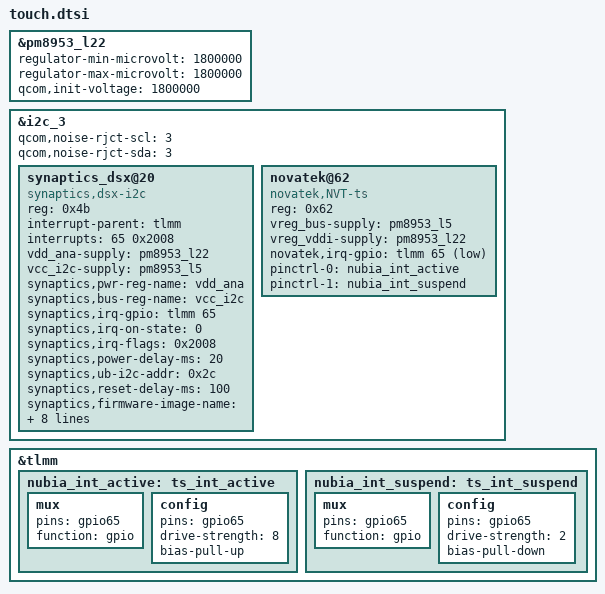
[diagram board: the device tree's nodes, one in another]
/*
 * Copyright (c) 2015-2016, The Linux Foundation. All rights reserved.
 *
 * This program is free software; you can redistribute it and/or modify
 * it under the terms of the GNU General Public License version 2 and
 * only version 2 as published by the Free Software Foundation.
 *
 * This program is distributed in the hope that it will be useful,
 * but WITHOUT ANY WARRANTY; without even the implied warranty of
 * MERCHANTABILITY or FITNESS FOR A PARTICULAR PURPOSE.  See the
 * GNU General Public License for more details.
 */


/*
 * ADD synaptics touch
 */

&pm8953_l22 {
	regulator-min-microvolt = <1800000>;
	regulator-max-microvolt = <1800000>;
	qcom,init-voltage = <1800000>;
};

&i2c_3 {
	status = "okay";

	qcom,noise-rjct-scl = <3>;
	qcom,noise-rjct-sda = <3>;

	synaptics_dsx@20 {
		status = "okay";
		compatible = "synaptics,dsx-i2c";
		reg = <0x4b>;
		interrupt-parent = <&tlmm>;
		interrupts = <65 0x2008>;
		vdd_ana-supply = <&pm8953_l22>;
		vcc_i2c-supply = <&pm8953_l5>;
		synaptics,pwr-reg-name = "vdd_ana";
		synaptics,bus-reg-name = "vcc_i2c";
		synaptics,irq-gpio = <&tlmm 65 0x2008>;
		synaptics,irq-on-state = <0>;
		synaptics,irq-flags = <0x2008>;  //IRQF_ONESHOT | IRQF_TRIGGER_LOW
		synaptics,power-delay-ms = <20>;
		synaptics,ub-i2c-addr = <0x2c>;
		synaptics,reset-delay-ms = <100>;
		synaptics,firmware-image-name = "nubia_tp_jdi_fw.img";
		pinctrl-names = "synaptics_pin_active", "synaptics_pin_suspend";
		pinctrl-0 = <&nubia_int_active>;
		pinctrl-1 = <&nubia_int_suspend>;
		synaptics.test = <0xaa55 0x1122 0x3344 0x8899>;
		synaptics,full_raw_limit_lower = <
			1767 1760 1731 1716 1749 1706 1709 1710 1676 1674 1706 1667 1661 1682 1637 1634 1682 1639 1656 1675 1655 1655 1679 1658 1675 1715 1674 1695 1730 1673 1707 1763
			1598 1619 1595 1593 1632 1599 1607 1615 1593 1596 1651 1596 1608 1627 1586 1591 1639 1601 1615 1639 1615 1620 1641 1622 1642 1685 1642 1667 1699 1642 1673 1731
			1595 1613 1592 1591 1632 1597 1606 1614 1595 1597 1639 1600 1604 1630 1590 1595 1644 1606 1621 1646 1622 1627 1650 1630 1650 1694 1648 1675 1705 1647 1677 1735
			1595 1611 1590 1590 1631 1595 1605 1617 1595 1602 1644 1602 1607 1641 1593 1599 1653 1609 1626 1655 1627 1634 1665 1635 1659 1704 1652 1681 1719 1647 1693 1746
			1602 1623 1588 1595 1634 1594 1610 1616 1596 1609 1645 1604 1615 1641 1595 1605 1657 1612 1635 1655 1632 1644 1668 1639 1666 1706 1654 1685 1719 1649 1694 1745
			1603 1617 1587 1593 1628 1592 1608 1617 1595 1608 1648 1604 1616 1643 1596 1607 1658 1613 1637 1658 1634 1647 1671 1640 1667 1706 1652 1683 1716 1647 1692 1741
			1603 1617 1587 1593 1628 1591 1607 1616 1595 1609 1648 1605 1617 1644 1597 1609 1659 1615 1639 1659 1635 1648 1671 1642 1668 1707 1652 1683 1716 1647 1694 1741
			1605 1617 1588 1593 1627 1590 1607 1615 1594 1608 1648 1605 1617 1644 1597 1609 1660 1615 1639 1662 1635 1649 1674 1641 1666 1709 1648 1683 1729 1645 1681 1713
			1600 1590 1589 1579 1626 1590 1601 1617 1594 1603 1648 1606 1610 1645 1597 1603 1660 1616 1635 1664 1636 1644 1671 1641 1659 1702 1648 1669 1706 1645 1674 1735
			1569 1549 1572 1539 1540 1590 1548 1558 1570 1545 1560 1593 1552 1560 1607 1554 1581 1602 1583 1589 1627 1590 1608 1647 1620 1617 1654 1612 1624 1631 1610 1651
			1554 1563 1595 1539 1558 1598 1548 1563 1574 1545 1566 1591 1551 1566 1606 1553 1587 1603 1582 1596 1622 1589 1615 1646 1620 1624 1657 1612 1639 1659 1610 1664
			1552 1567 1583 1539 1556 1593 1548 1562 1570 1545 1566 1586 1551 1565 1605 1551 1585 1601 1580 1594 1621 1588 1614 1646 1620 1624 1657 1612 1638 1658 1608 1658
			1551 1566 1583 1540 1557 1594 1549 1562 1570 1545 1565 1586 1550 1563 1603 1550 1583 1600 1579 1592 1619 1587 1612 1644 1618 1623 1656 1611 1636 1657 1606 1654
			1549 1566 1583 1541 1556 1594 1551 1563 1570 1544 1563 1584 1548 1561 1601 1548 1580 1597 1576 1588 1616 1583 1609 1637 1616 1622 1654 1610 1635 1657 1603 1652
			1549 1561 1586 1541 1554 1598 1550 1560 1571 1542 1556 1584 1545 1553 1599 1545 1572 1592 1570 1579 1614 1578 1597 1635 1611 1612 1647 1608 1625 1645 1599 1641
			1549 1553 1576 1541 1551 1591 1552 1556 1563 1540 1552 1576 1542 1549 1590 1541 1566 1580 1566 1571 1602 1572 1589 1625 1606 1606 1640 1604 1622 1641 1595 1635
			1553 1556 1577 1543 1551 1592 1553 1555 1560 1536 1548 1572 1538 1545 1585 1538 1561 1575 1561 1573 1612 1565 1584 1618 1600 1600 1638 1601 1617 1635 1592 1631
			1599 1594 1615 1580 1589 1626 1591 1592 1597 1575 1581 1612 1579 1586 1626 1579 1605 1624 1615 1624 1658 1637 1655 1699 1689 1696 1737 1708 1734 1759 1726 1782
		>;
		synaptics,full_raw_limit_upper = <
			3281 3268 3214 3187 3248 3169 3174 3176 3113 3109 3169 3096 3084 3124 3040 3034 3124 3044 3076 3111 3073 3073 3118 3079 3111 3184 3108 3147 3213 3108 3170 3274
			2969 3007 2963 2958 3032 2970 2984 2999 2958 2963 3067 2964 2985 3022 2946 2954 3044 2974 2999 3044 3000 3008 3048 3012 3050 3130 3049 3097 3155 3050 3106 3215
			2961 2996 2957 2956 3031 2965 2983 2998 2962 2967 3045 2972 2979 3027 2953 2962 3053 2982 3010 3056 3013 3022 3065 3027 3065 3145 3061 3110 3167 3058 3114 3223
			2963 2993 2952 2952 3028 2962 2982 3002 2963 2974 3054 2975 2985 3048 2958 2969 3069 2988 3019 3073 3021 3035 3092 3036 3081 3165 3068 3121 3193 3059 3144 3243
			2976 3013 2948 2962 3035 2960 2990 3001 2964 2989 3055 2978 2998 3048 2963 2981 3077 2995 3037 3074 3031 3053 3097 3044 3094 3168 3072 3129 3192 3063 3145 3240
			2977 3002 2946 2959 3024 2956 2987 3003 2962 2987 3060 2980 3001 3052 2965 2985 3079 2996 3040 3079 3035 3058 3102 3046 3096 3169 3068 3125 3187 3058 3143 3233
			2978 3002 2947 2959 3023 2955 2985 3002 2962 2988 3061 2981 3003 3053 2965 2988 3081 2999 3043 3081 3037 3061 3104 3049 3098 3170 3067 3126 3188 3058 3146 3233
			2981 3003 2948 2959 3022 2953 2985 3000 2959 2987 3061 2981 3003 3053 2965 2988 3083 3000 3044 3087 3036 3062 3109 3047 3095 3173 3061 3126 3212 3055 3122 3182
			2971 2952 2951 2932 3021 2952 2973 3003 2961 2976 3060 2982 2990 3054 2966 2977 3082 3001 3036 3091 3038 3053 3104 3048 3081 3160 3061 3099 3169 3054 3109 3223
			2913 2877 2920 2859 2860 2953 2875 2894 2916 2869 2897 2958 2883 2898 2984 2885 2936 2975 2940 2951 3022 2953 2985 3059 3008 3002 3071 2993 3015 3028 2990 3066
			2886 2903 2962 2857 2893 2968 2874 2902 2922 2869 2909 2955 2881 2909 2982 2883 2948 2977 2938 2963 3013 2952 3000 3058 3008 3017 3077 2994 3044 3082 2991 3091
			2883 2910 2939 2859 2890 2958 2875 2902 2915 2869 2908 2946 2880 2907 2980 2881 2944 2974 2934 2961 3011 2949 2998 3057 3008 3017 3078 2994 3041 3079 2986 3079
			2881 2909 2939 2859 2891 2960 2877 2901 2915 2869 2906 2945 2878 2904 2977 2878 2940 2971 2932 2956 3007 2947 2993 3052 3005 3014 3075 2992 3039 3076 2983 3072
			2876 2908 2939 2862 2890 2961 2880 2903 2916 2868 2904 2942 2876 2898 2974 2875 2935 2966 2927 2950 3000 2940 2989 3041 3001 3012 3071 2990 3036 3078 2976 3068
			2877 2899 2945 2861 2886 2967 2879 2898 2917 2864 2890 2943 2870 2884 2969 2869 2919 2956 2917 2932 2998 2930 2967 3036 2993 2994 3058 2986 3018 3056 2969 3047
			2876 2883 2927 2863 2880 2955 2882 2889 2902 2859 2881 2926 2865 2876 2952 2862 2908 2934 2908 2918 2976 2920 2951 3017 2983 2983 3046 2980 3012 3048 2962 3036
			2884 2889 2929 2866 2880 2957 2884 2887 2897 2853 2874 2919 2857 2869 2944 2856 2900 2925 2899 2922 2993 2907 2941 3006 2971 2971 3042 2973 3003 3037 2957 3028
			2969 2961 3000 2935 2951 3019 2956 2957 2965 2924 2937 2993 2932 2945 3020 2933 2981 3016 3000 3016 3079 3040 3074 3155 3137 3149 3226 3173 3220 3267 3205 3310
			>;
	};

	/* Novatek device tree node */
	novatek@62 {
		compatible = "novatek,NVT-ts";
		reg = <0x62>;
		status = "ok";

		vreg_bus-supply = <&pm8953_l5>;	//pullup
		/*add this to keep vddio enable after suspend*/
		vreg_vddi-supply = <&pm8953_l22>;

		novatek,irq-gpio = <&tlmm 65 0x2001>;
		pinctrl-names = "nvt_pin_active", "nvt_pin_suspend";
		pinctrl-0 = <&nubia_int_active>;
		pinctrl-1 = <&nubia_int_suspend>;
	};
};

&tlmm{
	/*nubia touch screen pinctrl*/
	nubia_int_active: ts_int_active {
		mux {
			pins = "gpio65";
			function = "gpio";
		};
		config {
			pins = "gpio65";
			drive-strength = <8>;
			bias-pull-up;
		};
	};

	nubia_int_suspend: ts_int_suspend {
		mux {
			pins = "gpio65";
			function = "gpio";
		};

		config {
			pins = "gpio65";
			drive-strength = <2>;
			bias-pull-down;
		};
	};
};
